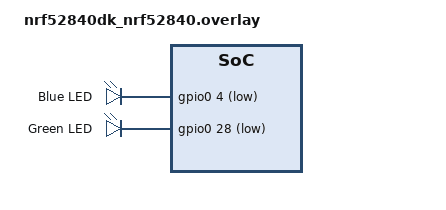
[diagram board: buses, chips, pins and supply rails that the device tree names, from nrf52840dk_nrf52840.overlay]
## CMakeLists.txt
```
# SPDX-License-Identifier: Apache-2.0

cmake_minimum_required(VERSION 3.20.0)

find_package(Zephyr REQUIRED HINTS $ENV{ZEPHYR_BASE})
project(led_blink)

target_sources(app PRIVATE src/main.c src/gpio_operations.c)
```

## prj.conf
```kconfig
# Include source code for GPIOs
CONFIG_GPIO=y
```

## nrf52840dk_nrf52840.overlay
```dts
// To get started, press Ctrl+Space to bring up the completion menu and view the available nodes.

// You can also use the buttons in the sidebar to perform actions on nodes.
// Actions currently available include:

// * Enabling / disabling the node
// * Adding the bus to a bus
// * Removing the node
// * Connecting ADC channels

// For more help, browse the DeviceTree documentation at https://docs.zephyrproject.org/latest/guides/dts/index.html
// You can also visit the nRF DeviceTree extension documentation at https://nrfconnect.github.io/vscode-nrf-connect/devicetree/nrfdevicetree.html

/ { 
    aliases {
        blueled = &blueLED;
        greenled = &greenLED;
    };

    newLEDs {
        compatible = "gpio-leds";
        blueLED: led_blue {
                gpios = <&gpio0 4 GPIO_ACTIVE_LOW>;
                label = "Blue LED";
        };
        greenLED: led_green {
            gpios = <&gpio0 28 GPIO_ACTIVE_LOW>;
            label = "Green LED";
        };
    };
        
};
```

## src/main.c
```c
/*
 * Copyright (c) 2012-2014 Wind River Systems, Inc.
 *
 * SPDX-License-Identifier: Apache-2.0
 */

#include "headers.h"
#include "zephyr/kernel.h"



void main(void)
{
	printk("Hello World! \r\n");
	gpio_configure();
	
	while(1)
	{
		toggle_both();
		k_msleep(LED_DELAY);
	}
}
```

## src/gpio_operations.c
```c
#include"headers.h"


//------get the pointer to the LEDs-----------
static const struct gpio_dt_spec blueLED = GPIO_DT_SPEC_GET(BLUE_LED, gpios);
static const struct gpio_dt_spec greenLED = GPIO_DT_SPEC_GET(GREEN_LED, gpios);

void gpio_configure()
{
    printf("Inside GPIO Configurations\r\n");

    // Wait for the device to be ready
    if (!device_is_ready(blueLED.port)) {
		return;
	}
    if (!device_is_ready(greenLED.port)) {
		return;
	}

	// Set the direction of GPIOs
	gpio_pin_configure_dt(&blueLED, GPIO_OUTPUT);
    gpio_pin_configure_dt(&greenLED, GPIO_OUTPUT);
}

/*
    toggle both LEDs
*/

void toggle_both()
{
    gpio_pin_toggle_dt(&blueLED);
    gpio_pin_toggle_dt(&greenLED);
}
```

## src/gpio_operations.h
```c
#ifndef GPIO_OPERATIONS_H
#define GPIO_OPERATIONS_H

/* LED Delay */
#define LED_DELAY   5000

//-----get the node reference----
#define BLUE_LED DT_ALIAS(blueled)
#define GREEN_LED DT_ALIAS(greenled)

/*
    This function will set the GOPIO configurations
*/
void gpio_configure(void);

/*
    This function toggle both the LEDs
*/
void toggle_both(void);

#endif
```

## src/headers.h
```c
#include <stdio.h>
#include <zephyr/kernel.h>
#include <zephyr/drivers/gpio.h>

/*---My Custom Functions----*/
#include "gpio_operations.h"
```
